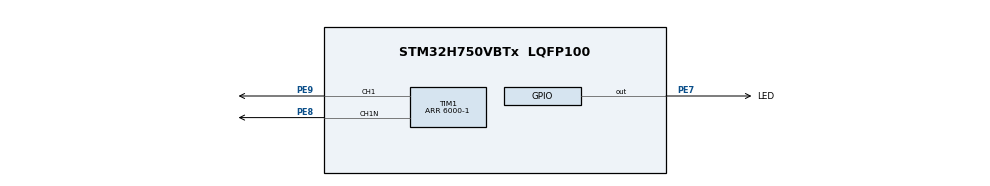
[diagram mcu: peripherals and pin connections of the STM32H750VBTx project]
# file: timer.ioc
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Mcu.Family=STM32H7
Mcu.Name=STM32H750VBTx
Mcu.Package=LQFP100
NVIC.PriorityGroup=NVIC_PRIORITYGROUP_4
NVIC.TIM17_IRQn=true\:15\:0\:false\:false\:true\:false\:true\:true
NVIC.TIM1_UP_IRQn=true\:0\:0\:false\:false\:true\:true\:true\:true
NVIC.TimeBase=TIM17_IRQn
NVIC.TimeBaseIP=TIM17
PA13\ (JTMS/SWDIO).Mode=Serial_Wire
PA13\ (JTMS/SWDIO).Signal=DEBUG_JTMS-SWDIO
PA14\ (JTCK/SWCLK).Mode=Serial_Wire
PA14\ (JTCK/SWCLK).Signal=DEBUG_JTCK-SWCLK
PE7.GPIO_Label=LED
PE7.Signal=GPIO_Output
PE8.Mode=PWM Generation1 CH1 CH1N
PE8.Signal=TIM1_CH1N
PE9.Signal=S_TIM1_CH1
PH0-OSC_IN\ (PH0).Mode=HSE-External-Oscillator
PH0-OSC_IN\ (PH0).Signal=RCC_OSC_IN
PH1-OSC_OUT\ (PH1).Mode=HSE-External-Oscillator
PH1-OSC_OUT\ (PH1).Signal=RCC_OSC_OUT
ProjectManager.HeapSize=0x200
ProjectManager.StackSize=0x400
ProjectManager.TargetToolchain=STM32CubeIDE
RCC.ADCFreq_Value=50390625
RCC.APB1Freq_Value=60000000
RCC.APB2Freq_Value=60000000
RCC.APB3Freq_Value=60000000
RCC.APB4Freq_Value=60000000
RCC.CortexFreq_Value=240000000
RCC.D1PPRE=RCC_APB3_DIV2
RCC.D2PPRE1=RCC_APB1_DIV2
RCC.D2PPRE2=RCC_APB2_DIV2
RCC.D3PPRE=RCC_APB4_DIV2
RCC.DIVM1=25
RCC.DIVN1=480
RCC.HCLKFreq_Value=120000000
RCC.HPRE=RCC_HCLK_DIV2
RCC.PLLSourceVirtual=RCC_PLLSOURCE_HSE
RCC.SYSCLKFreq_VALUE=240000000
RCC.SYSCLKSource=RCC_SYSCLKSOURCE_PLLCLK
RCC.USBFreq_Value=240000000
SH.S_TIM1_CH1.0=TIM1_CH1,PWM Generation1 CH1 CH1N
TIM1.Channel-PWM\ Generation1\ CH1\ CH1N=TIM_CHANNEL_1
TIM1.CounterMode=TIM_COUNTERMODE_CENTERALIGNED1
TIM1.DeadTime=36
TIM1.OCNPolarity_1=TIM_OCNPOLARITY_LOW
TIM1.OCPolarity_1=TIM_OCPOLARITY_LOW
TIM1.Period=6000-1
TIM1.RepetitionCounter=1
VP_HRTIM_VS_hrtimMasterTimerNoOutput.Mode=MasterTimer
VP_SYS_VS_tim17.Mode=TIM17
board=custom

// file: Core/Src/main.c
/* USER CODE BEGIN Header */
/**
  ******************************************************************************
  * @file           : main.c
  * @brief          : Main program body
  ******************************************************************************
  * @attention
  *
  * Copyright (c) 2024 STMicroelectronics.
  * All rights reserved.
  *
  * This software is licensed under terms that can be found in the LICENSE file
  * in the root directory of this software component.
  * If no LICENSE file comes with this software, it is provided AS-IS.
  *
  ******************************************************************************
  */
/* USER CODE END Header */
#include "main.h"

HRTIM_HandleTypeDef hhrtim;

TIM_HandleTypeDef htim1;

void SystemClock_Config(void);
static void MX_GPIO_Init(void);
static void MX_TIM1_Init(void);
static void MX_HRTIM_Init(void);

int main(void)
{

  /* MCU Configuration--------------------------------------------------------*/

  /* Reset of all peripherals, Initializes the Flash interface and the Systick. */
  HAL_Init();

  /* Configure the system clock */
  SystemClock_Config();

  /* Initialize all configured peripherals */
  MX_GPIO_Init();
  MX_TIM1_Init();
  MX_HRTIM_Init();
  /* USER CODE BEGIN 2 */
  setup();
  /* USER CODE END 2 */

  /* Infinite loop */
  while (1)
  {

    /* USER CODE BEGIN 3 */
	  loop();
  }
  /* USER CODE END 3 */
}

void SystemClock_Config(void)
{
  RCC_OscInitTypeDef RCC_OscInitStruct = {0};
  RCC_ClkInitTypeDef RCC_ClkInitStruct = {0};

  /** Supply configuration update enable
  */
  HAL_PWREx_ConfigSupply(PWR_LDO_SUPPLY);

  /** Configure the main internal regulator output voltage
  */
  __HAL_PWR_VOLTAGESCALING_CONFIG(PWR_REGULATOR_VOLTAGE_SCALE2);

  while(!__HAL_PWR_GET_FLAG(PWR_FLAG_VOSRDY)) {}

  /** Initializes the RCC Oscillators according to the specified parameters
  * in the RCC_OscInitTypeDef structure.
  */
  RCC_OscInitStruct.OscillatorType = RCC_OSCILLATORTYPE_HSE;
  RCC_OscInitStruct.HSEState = RCC_HSE_ON;
  RCC_OscInitStruct.PLL.PLLState = RCC_PLL_ON;
  RCC_OscInitStruct.PLL.PLLSource = RCC_PLLSOURCE_HSE;
  RCC_OscInitStruct.PLL.PLLM = 25;
  RCC_OscInitStruct.PLL.PLLN = 480;
  RCC_OscInitStruct.PLL.PLLP = 2;
  RCC_OscInitStruct.PLL.PLLQ = 2;
  RCC_OscInitStruct.PLL.PLLR = 2;
  RCC_OscInitStruct.PLL.PLLRGE = RCC_PLL1VCIRANGE_0;
  RCC_OscInitStruct.PLL.PLLVCOSEL = RCC_PLL1VCOWIDE;
  RCC_OscInitStruct.PLL.PLLFRACN = 0;
  if (HAL_RCC_OscConfig(&RCC_OscInitStruct) != HAL_OK)
  {
    Error_Handler();
  }

  /** Initializes the CPU, AHB and APB buses clocks
  */
  RCC_ClkInitStruct.ClockType = RCC_CLOCKTYPE_HCLK|RCC_CLOCKTYPE_SYSCLK
                              |RCC_CLOCKTYPE_PCLK1|RCC_CLOCKTYPE_PCLK2
                              |RCC_CLOCKTYPE_D3PCLK1|RCC_CLOCKTYPE_D1PCLK1;
  RCC_ClkInitStruct.SYSCLKSource = RCC_SYSCLKSOURCE_PLLCLK;
  RCC_ClkInitStruct.SYSCLKDivider = RCC_SYSCLK_DIV1;
  RCC_ClkInitStruct.AHBCLKDivider = RCC_HCLK_DIV2;
  RCC_ClkInitStruct.APB3CLKDivider = RCC_APB3_DIV2;
  RCC_ClkInitStruct.APB1CLKDivider = RCC_APB1_DIV2;
  RCC_ClkInitStruct.APB2CLKDivider = RCC_APB2_DIV2;
  RCC_ClkInitStruct.APB4CLKDivider = RCC_APB4_DIV2;

  if (HAL_RCC_ClockConfig(&RCC_ClkInitStruct, FLASH_LATENCY_2) != HAL_OK)
  {
    Error_Handler();
  }
}

static void MX_HRTIM_Init(void)
{

  HRTIM_TimeBaseCfgTypeDef pTimeBaseCfg = {0};
  HRTIM_TimerCfgTypeDef pTimerCfg = {0};

  hhrtim.Instance = HRTIM1;
  hhrtim.Init.HRTIMInterruptResquests = HRTIM_IT_NONE;
  hhrtim.Init.SyncOptions = HRTIM_SYNCOPTION_NONE;
  if (HAL_HRTIM_Init(&hhrtim) != HAL_OK)
  {
    Error_Handler();
  }
  pTimeBaseCfg.Period = 0xFFFD;
  pTimeBaseCfg.RepetitionCounter = 0x00;
  pTimeBaseCfg.PrescalerRatio = HRTIM_PRESCALERRATIO_DIV1;
  pTimeBaseCfg.Mode = HRTIM_MODE_CONTINUOUS;
  if (HAL_HRTIM_TimeBaseConfig(&hhrtim, HRTIM_TIMERINDEX_MASTER, &pTimeBaseCfg) != HAL_OK)
  {
    Error_Handler();
  }
  pTimerCfg.InterruptRequests = HRTIM_MASTER_IT_NONE;
  pTimerCfg.DMARequests = HRTIM_MASTER_DMA_NONE;
  pTimerCfg.DMASrcAddress = 0x0000;
  pTimerCfg.DMADstAddress = 0x0000;
  pTimerCfg.DMASize = 0x1;
  pTimerCfg.HalfModeEnable = HRTIM_HALFMODE_DISABLED;
  pTimerCfg.StartOnSync = HRTIM_SYNCSTART_DISABLED;
  pTimerCfg.ResetOnSync = HRTIM_SYNCRESET_DISABLED;
  pTimerCfg.DACSynchro = HRTIM_DACSYNC_NONE;
  pTimerCfg.PreloadEnable = HRTIM_PRELOAD_DISABLED;
  pTimerCfg.UpdateGating = HRTIM_UPDATEGATING_INDEPENDENT;
  pTimerCfg.BurstMode = HRTIM_TIMERBURSTMODE_MAINTAINCLOCK;
  pTimerCfg.RepetitionUpdate = HRTIM_UPDATEONREPETITION_DISABLED;
  if (HAL_HRTIM_WaveformTimerConfig(&hhrtim, HRTIM_TIMERINDEX_MASTER, &pTimerCfg) != HAL_OK)
  {
    Error_Handler();
  }

}

static void MX_TIM1_Init(void)
{

  TIM_MasterConfigTypeDef sMasterConfig = {0};
  TIM_OC_InitTypeDef sConfigOC = {0};
  TIM_BreakDeadTimeConfigTypeDef sBreakDeadTimeConfig = {0};

  htim1.Instance = TIM1;
  htim1.Init.Prescaler = 0;
  htim1.Init.CounterMode = TIM_COUNTERMODE_CENTERALIGNED1;
  htim1.Init.Period = 6000-1;
  htim1.Init.ClockDivision = TIM_CLOCKDIVISION_DIV1;
  htim1.Init.RepetitionCounter = 1;
  htim1.Init.AutoReloadPreload = TIM_AUTORELOAD_PRELOAD_DISABLE;
  if (HAL_TIM_PWM_Init(&htim1) != HAL_OK)
  {
    Error_Handler();
  }
  sMasterConfig.MasterOutputTrigger = TIM_TRGO_RESET;
  sMasterConfig.MasterOutputTrigger2 = TIM_TRGO2_RESET;
  sMasterConfig.MasterSlaveMode = TIM_MASTERSLAVEMODE_DISABLE;
  if (HAL_TIMEx_MasterConfigSynchronization(&htim1, &sMasterConfig) != HAL_OK)
  {
    Error_Handler();
  }
  sConfigOC.OCMode = TIM_OCMODE_PWM1;
  sConfigOC.Pulse = 0;
  sConfigOC.OCPolarity = TIM_OCPOLARITY_LOW;
  sConfigOC.OCNPolarity = TIM_OCNPOLARITY_LOW;
  sConfigOC.OCFastMode = TIM_OCFAST_DISABLE;
  sConfigOC.OCIdleState = TIM_OCIDLESTATE_RESET;
  sConfigOC.OCNIdleState = TIM_OCNIDLESTATE_RESET;
  if (HAL_TIM_PWM_ConfigChannel(&htim1, &sConfigOC, TIM_CHANNEL_1) != HAL_OK)
  {
    Error_Handler();
  }
  sBreakDeadTimeConfig.OffStateRunMode = TIM_OSSR_DISABLE;
  sBreakDeadTimeConfig.OffStateIDLEMode = TIM_OSSI_DISABLE;
  sBreakDeadTimeConfig.LockLevel = TIM_LOCKLEVEL_OFF;
  sBreakDeadTimeConfig.DeadTime = 36;
  sBreakDeadTimeConfig.BreakState = TIM_BREAK_DISABLE;
  sBreakDeadTimeConfig.BreakPolarity = TIM_BREAKPOLARITY_HIGH;
  sBreakDeadTimeConfig.BreakFilter = 0;
  sBreakDeadTimeConfig.Break2State = TIM_BREAK2_DISABLE;
  sBreakDeadTimeConfig.Break2Polarity = TIM_BREAK2POLARITY_HIGH;
  sBreakDeadTimeConfig.Break2Filter = 0;
  sBreakDeadTimeConfig.AutomaticOutput = TIM_AUTOMATICOUTPUT_DISABLE;
  if (HAL_TIMEx_ConfigBreakDeadTime(&htim1, &sBreakDeadTimeConfig) != HAL_OK)
  {
    Error_Handler();
  }
  HAL_TIM_MspPostInit(&htim1);

}

static void MX_GPIO_Init(void)
{
  GPIO_InitTypeDef GPIO_InitStruct = {0};

  /* GPIO Ports Clock Enable */
  __HAL_RCC_GPIOH_CLK_ENABLE();
  __HAL_RCC_GPIOE_CLK_ENABLE();
  __HAL_RCC_GPIOA_CLK_ENABLE();

  /*Configure GPIO pin Output Level */
  HAL_GPIO_WritePin(LED_GPIO_Port, LED_Pin, GPIO_PIN_RESET);

  /*Configure GPIO pin : LED_Pin */
  GPIO_InitStruct.Pin = LED_Pin;
  GPIO_InitStruct.Mode = GPIO_MODE_OUTPUT_PP;
  GPIO_InitStruct.Pull = GPIO_NOPULL;
  GPIO_InitStruct.Speed = GPIO_SPEED_FREQ_LOW;
  HAL_GPIO_Init(LED_GPIO_Port, &GPIO_InitStruct);

}

void HAL_TIM_PeriodElapsedCallback(TIM_HandleTypeDef *htim)
{
  /* USER CODE BEGIN Callback 0 */
	  if (htim->Instance == TIM1) {
		  timer_call_back();
	  }
  /* USER CODE END Callback 0 */
  if (htim->Instance == TIM17) {
    HAL_IncTick();
  }
}

void Error_Handler(void)
{
  __disable_irq();
  while (1)
  {
  }
}
